AUTOSAR XML (schema 00044)
package /ComponentTypes
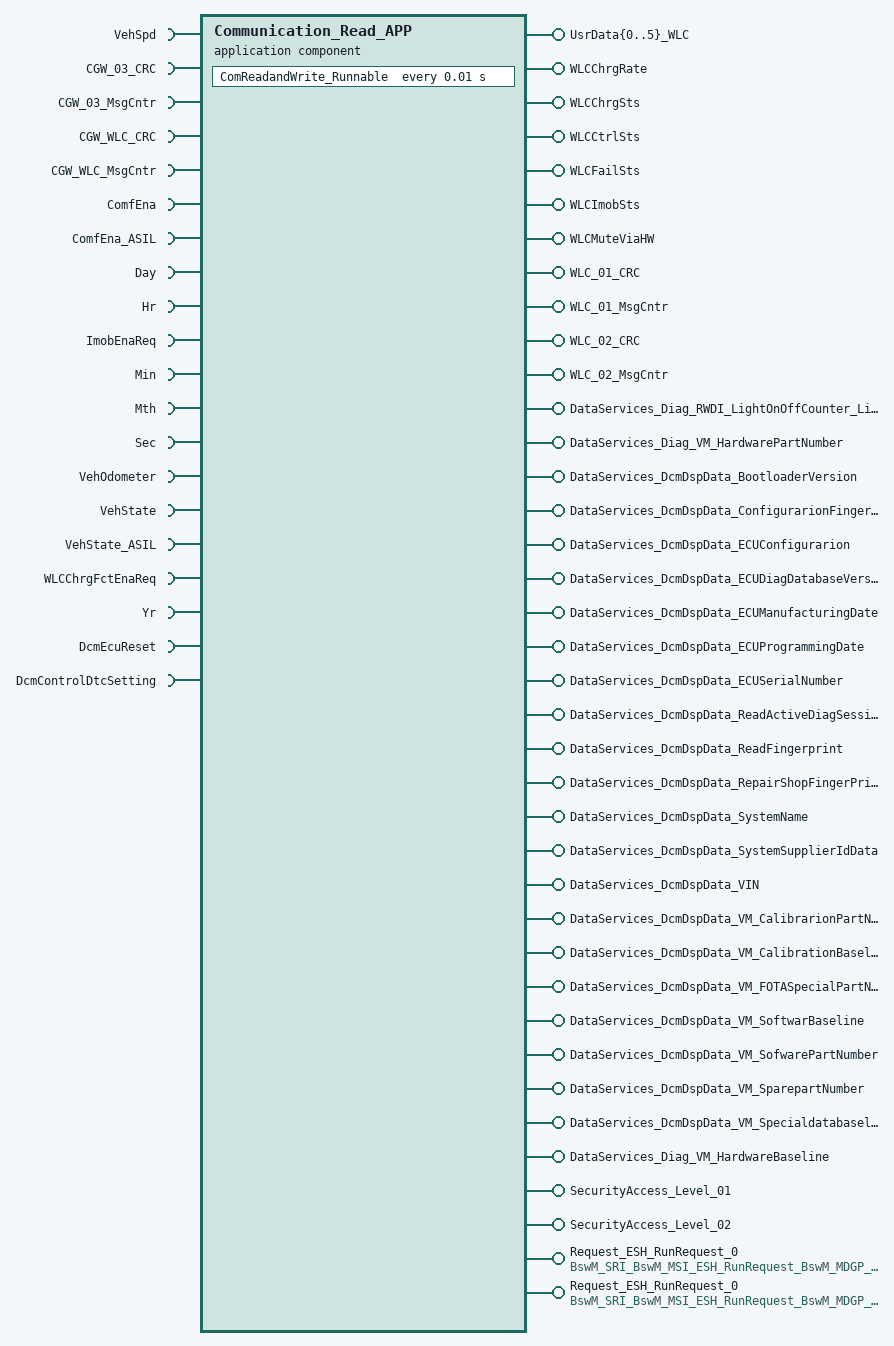
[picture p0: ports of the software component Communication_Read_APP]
  application sw component type Communication_Read_APP
    18 x require port:
      VehSpd: nonqueued-receiver-com-spec{data-element=VehSpd, filter=data-filter-type=ALWAYS, init-value=0}, required-interface=VehSpd
      CGW_03_CRC: nonqueued-receiver-com-spec{data-element=CGW_03_CRC, filter=data-filter-type=ALWAYS, init-value=0}, required-interface=CGW_03_CRC
      CGW_03_MsgCntr: nonqueued-receiver-com-spec{data-element=CGW_03_MsgCntr, filter=data-filter-type=ALWAYS, init-value=0}, required-interface=CGW_03_MsgCntr
      CGW_WLC_CRC: nonqueued-receiver-com-spec{data-element=CGW_WLC_CRC, filter=data-filter-type=ALWAYS, init-value=0}, required-interface=CGW_WLC_CRC
      CGW_WLC_MsgCntr: nonqueued-receiver-com-spec{data-element=CGW_WLC_MsgCntr, filter=data-filter-type=ALWAYS, init-value=0}, required-interface=CGW_WLC_MsgCntr
      ComfEna: nonqueued-receiver-com-spec{data-element=ComfEna, filter=data-filter-type=ALWAYS, init-value=0}, required-interface=ComfEna
      ComfEna_ASIL: nonqueued-receiver-com-spec{data-element=ComfEna_ASIL, filter=data-filter-type=ALWAYS, init-value=0}, required-interface=ComfEna_ASIL
      Day: nonqueued-receiver-com-spec{data-element=Day, filter=data-filter-type=ALWAYS, init-value=0}, required-interface=Day
      Hr: nonqueued-receiver-com-spec{data-element=Hr, filter=data-filter-type=ALWAYS, init-value=0}, required-interface=Hr
      ImobEnaReq: nonqueued-receiver-com-spec{data-element=ImobEnaReq, filter=data-filter-type=ALWAYS, init-value=0}, required-interface=ImobEnaReq
      Min: nonqueued-receiver-com-spec{data-element=Min, filter=data-filter-type=ALWAYS, init-value=0}, required-interface=Min
      Mth: nonqueued-receiver-com-spec{data-element=Mth, filter=data-filter-type=ALWAYS, init-value=0}, required-interface=Mth
      Sec: nonqueued-receiver-com-spec{data-element=Sec, filter=data-filter-type=ALWAYS, init-value=0}, required-interface=Sec
      VehOdometer: nonqueued-receiver-com-spec{data-element=VehOdometer, filter=data-filter-type=ALWAYS, init-value=0}, required-interface=VehOdometer
      VehState: nonqueued-receiver-com-spec{data-element=VehState, filter=data-filter-type=ALWAYS, init-value=0}, required-interface=VehState
      VehState_ASIL: nonqueued-receiver-com-spec{data-element=VehState_ASIL, filter=data-filter-type=ALWAYS, init-value=0}, required-interface=VehState_ASIL
      WLCChrgFctEnaReq: nonqueued-receiver-com-spec{data-element=WLCChrgFctEnaReq, filter=data-filter-type=ALWAYS, init-value=0}, required-interface=WLCChrgFctEnaReq
      Yr: nonqueued-receiver-com-spec{data-element=Yr, filter=data-filter-type=ALWAYS, init-value=0}, required-interface=Yr
    16 x provide port:
      UsrData{0..5}_WLC: nonqueued-sender-com-spec{data-element=UsrData{0..5}_WLC, init-value=0}, provided-interface=UsrData{0..5}_WLC
      WLCChrgRate: nonqueued-sender-com-spec{data-element=WLCChrgRate, init-value=0}, provided-interface=WLCChrgRate
      WLCChrgSts: nonqueued-sender-com-spec{data-element=WLCChrgSts, init-value=0}, provided-interface=WLCChrgSts
      WLCCtrlSts: nonqueued-sender-com-spec{data-element=WLCCtrlSts, init-value=0}, provided-interface=WLCCtrlSts
      WLCFailSts: nonqueued-sender-com-spec{data-element=WLCFailSts, init-value=0}, provided-interface=WLCFailSts
      WLCImobSts: nonqueued-sender-com-spec{data-element=WLCImobSts, init-value=0}, provided-interface=WLCImobSts
      WLCMuteViaHW: nonqueued-sender-com-spec{data-element=WLCMuteViaHW, init-value=0}, provided-interface=WLCMuteViaHW
      WLC_01_CRC: nonqueued-sender-com-spec{data-element=WLC_01_CRC, init-value=0}, provided-interface=WLC_01_CRC
      WLC_01_MsgCntr: nonqueued-sender-com-spec{data-element=WLC_01_MsgCntr, init-value=0}, provided-interface=WLC_01_MsgCntr
      WLC_02_CRC: nonqueued-sender-com-spec{data-element=WLC_02_CRC, init-value=0}, provided-interface=WLC_02_CRC
      WLC_02_MsgCntr: nonqueued-sender-com-spec{data-element=WLC_02_MsgCntr, init-value=0}, provided-interface=WLC_02_MsgCntr
    require port DcmEcuReset: mode-switch-receiver-com-spec=DcmEcuReset, required-interface=DcmEcuReset
    23 x provide port:
      DataServices_Diag_RWDI_LightOnOffCounter_LightOnOffCounter_Value: provided-interface=DataServices_Diag_RWDI_LightOnOffCounter_LightOnOffCounter_Value
        provided-com-specs:
          operation=ReadData, queue-length=1
          operation=ConditionCheckRead, queue-length=1
          operation=WriteData, queue-length=1
      DataServices_Diag_VM_HardwarePartNumber: provided-interface=DataServices_Diag_VM_HardwarePartNumber
        provided-com-specs:
          operation=ReadData, queue-length=1
          operation=ConditionCheckRead, queue-length=1
          operation=WriteData, queue-length=1
      DataServices_DcmDspData_BootloaderVersion: provided-interface=DataServices_DcmDspData_BootloaderVersion
        provided-com-specs:
          operation=ReadData, queue-length=1
          operation=ReadDataLength, queue-length=1
          operation=ConditionCheckRead, queue-length=1
      DataServices_DcmDspData_ConfigurarionFingerprint: provided-interface=DataServices_DcmDspData_ConfigurarionFingerprint
        provided-com-specs:
          operation=ReadData, queue-length=1
          operation=ConditionCheckRead, queue-length=1
          operation=WriteData, queue-length=1
      DataServices_DcmDspData_ECUConfigurarion: provided-interface=DataServices_DcmDspData_ECUConfigurarion
        provided-com-specs:
          operation=ReadData, queue-length=1
          operation=ConditionCheckRead, queue-length=1
          operation=WriteData, queue-length=1
      DataServices_DcmDspData_ECUDiagDatabaseVersion: provided-com-specs=[{operation=ReadData, queue-length=1}, {operation=ConditionCheckRead, queue-length=1}], provided-interface=DataServices_DcmDspData_ECUDiagDatabaseVersion
      DataServices_DcmDspData_ECUManufacturingDate: provided-com-specs=[{operation=ReadData, queue-length=1}, {operation=ConditionCheckRead, queue-length=1}], provided-interface=DataServices_DcmDspData_ECUManufacturingDate
      DataServices_DcmDspData_ECUProgrammingDate: provided-com-specs=[{operation=ReadData, queue-length=1}, {operation=ConditionCheckRead, queue-length=1}], provided-interface=DataServices_DcmDspData_ECUProgrammingDate
      DataServices_DcmDspData_ECUSerialNumber: provided-com-specs=[{operation=ReadData, queue-length=1}, {operation=ConditionCheckRead, queue-length=1}], provided-interface=DataServices_DcmDspData_ECUSerialNumber
      DataServices_DcmDspData_ReadActiveDiagSession: provided-com-specs=[{operation=ReadData, queue-length=1}, {operation=ConditionCheckRead, queue-length=1}], provided-interface=DataServices_DcmDspData_ReadActiveDiagSession
      DataServices_DcmDspData_ReadFingerprint: provided-com-specs=[{operation=ReadData, queue-length=1}, {operation=ConditionCheckRead, queue-length=1}], provided-interface=DataServices_DcmDspData_ReadFingerprint
      DataServices_DcmDspData_RepairShopFingerPrint: provided-interface=DataServices_DcmDspData_RepairShopFingerPrint
        provided-com-specs:
          operation=ReadData, queue-length=1
          operation=ConditionCheckRead, queue-length=1
          operation=WriteData, queue-length=1
      DataServices_DcmDspData_SystemName: provided-interface=DataServices_DcmDspData_SystemName
        provided-com-specs:
          operation=ReadData, queue-length=1
          operation=ReadDataLength, queue-length=1
          operation=ConditionCheckRead, queue-length=1
      DataServices_DcmDspData_SystemSupplierIdData: provided-com-specs=[{operation=ReadData, queue-length=1}, {operation=ConditionCheckRead, queue-length=1}], provided-interface=DataServices_DcmDspData_SystemSupplierIdData
      DataServices_DcmDspData_VIN: provided-interface=DataServices_DcmDspData_VIN
        provided-com-specs:
          operation=ReadData, queue-length=1
          operation=ConditionCheckRead, queue-length=1
          operation=WriteData, queue-length=1
      DataServices_DcmDspData_VM_CalibrarionPartNumber: provided-interface=DataServices_DcmDspData_VM_CalibrarionPartNumber
        provided-com-specs:
          operation=ReadData, queue-length=1
          operation=ConditionCheckRead, queue-length=1
          operation=WriteData, queue-length=1
      DataServices_DcmDspData_VM_CalibrationBaseline: provided-interface=DataServices_DcmDspData_VM_CalibrationBaseline
        provided-com-specs:
          operation=ReadData, queue-length=1
          operation=ConditionCheckRead, queue-length=1
          operation=WriteData, queue-length=1
      DataServices_DcmDspData_VM_FOTASpecialPartNumber: provided-interface=DataServices_DcmDspData_VM_FOTASpecialPartNumber
        provided-com-specs:
          operation=ReadData, queue-length=1
          operation=ConditionCheckRead, queue-length=1
          operation=WriteData, queue-length=1
      DataServices_DcmDspData_VM_SoftwarBaseline: provided-interface=DataServices_DcmDspData_VM_SoftwarBaseline
        provided-com-specs:
          operation=ReadData, queue-length=1
          operation=ConditionCheckRead, queue-length=1
          operation=WriteData, queue-length=1
      DataServices_DcmDspData_VM_SofwarePartNumber: provided-interface=DataServices_DcmDspData_VM_SofwarePartNumber
        provided-com-specs:
          operation=ReadData, queue-length=1
          operation=ConditionCheckRead, queue-length=1
          operation=WriteData, queue-length=1
      DataServices_DcmDspData_VM_SparepartNumber: provided-interface=DataServices_DcmDspData_VM_SparepartNumber
        provided-com-specs:
          operation=ReadData, queue-length=1
          operation=ConditionCheckRead, queue-length=1
          operation=WriteData, queue-length=1
      DataServices_DcmDspData_VM_Specialdatabaseline: provided-interface=DataServices_DcmDspData_VM_Specialdatabaseline
        provided-com-specs:
          operation=ReadData, queue-length=1
          operation=ReadDataLength, queue-length=1
          operation=ConditionCheckRead, queue-length=1
          operation=WriteData, queue-length=1
      DataServices_Diag_VM_HardwareBaseline: provided-interface=DataServices_Diag_VM_HardwareBaseline
        provided-com-specs:
          operation=ReadData, queue-length=1
          operation=ConditionCheckRead, queue-length=1
          operation=WriteData, queue-length=1
    require port DcmControlDtcSetting: mode-switch-receiver-com-spec=DcmControlDtcSetting, required-interface=DcmControlDtcSetting
    4 x provide port:
      SecurityAccess_Level_01: provided-com-specs=[{operation=GetSeed, queue-length=1}, {operation=CompareKey, queue-length=1}], provided-interface=SecurityAccess_Level_01
      SecurityAccess_Level_02: provided-com-specs=[{operation=GetSeed, queue-length=1}, {operation=CompareKey, queue-length=1}], provided-interface=SecurityAccess_Level_02
      Request_ESH_RunRequest_0: nonqueued-sender-com-spec=requestedMode, provided-interface=BswM_SRI_BswM_MSI_ESH_RunRequest_BswM_MDGP_ESH_RunRequest
      Request_ESH_RunRequest_0: nonqueued-sender-com-spec=requestedMode, provided-interface=BswM_SRI_BswM_MSI_ESH_RunRequest_BswM_MDGP_ESH_RunRequest
    behavior Communication_Read_APP_InternalBehavior
      timing event TMT_WLCAPP_Runnable: start-on-event=ComReadandWrite_Runnable, period=0.01
      67 x operation invoked event:
        OIT_DataServices_Diag_RWDI_LightOnOffCounter_LightOnOffCounter_Value_WriteData_DataServices_Diag_RWDI_LightOnOffCounter_9798F8A6: start-on-event=DataServices_Diag_RWDI_LightOnOffCounter_LightOnOffCounter_Value_WriteData, operation=DataServices_Diag_RWDI_LightOnOffCounter_LightOnOffCounter_Value.WriteData
        OIT_DataServices_Diag_RWDI_LightOnOffCounter_LightOnOffCounter_Value_ConditionCheckRead_DataServices_Diag_RWDI_LightOnOf2065F94A: start-on-event=DataServices_Diag_RWDI_LightOnOffCounter_LightOnOffCounter_Value_ConditionCheckRead, operation=DataServices_Diag_RWDI_LightOnOffCounter_LightOnOffCounter_Value.ConditionCheckRead
        OIT_DataServices_Diag_RWDI_LightOnOffCounter_LightOnOffCounter_Value_ReadData_DataServices_Diag_RWDI_LightOnOffCounter_LBCB6C10A: start-on-event=DataServices_Diag_RWDI_LightOnOffCounter_LightOnOffCounter_Value_ReadData, operation=DataServices_Diag_RWDI_LightOnOffCounter_LightOnOffCounter_Value.ReadData
        OIT_DataServices_Diag_VM_HardwarePartNumber_WriteData_DataServices_Diag_VM_HardwarePartNumber_WriteData: start-on-event=DataServices_Diag_VM_HardwarePartNumber_WriteData, operation=DataServices_Diag_VM_HardwarePartNumber.WriteData
        OIT_DataServices_Diag_VM_HardwarePartNumber_ConditionCheckRead_DataServices_Diag_VM_HardwarePartNumber_ConditionCheckRead: start-on-event=DataServices_Diag_VM_HardwarePartNumber_ConditionCheckRead, operation=DataServices_Diag_VM_HardwarePartNumber.ConditionCheckRead
        OIT_DataServices_Diag_VM_HardwarePartNumber_ReadData_DataServices_Diag_VM_HardwarePartNumber_ReadData: start-on-event=DataServices_Diag_VM_HardwarePartNumber_ReadData, operation=DataServices_Diag_VM_HardwarePartNumber.ReadData
        OIT_DataServices_DcmDspData_BootloaderVersion_ConditionCheckRead_DataServices_DcmDspData_BootloaderVersion_ConditionCheckRead: start-on-event=DataServices_DcmDspData_BootloaderVersion_ConditionCheckRead, operation=DataServices_DcmDspData_BootloaderVersion.ConditionCheckRead
        OIT_DataServices_DcmDspData_BootloaderVersion_ReadDataLength_DataServices_DcmDspData_BootloaderVersion_ReadDataLength: start-on-event=DataServices_DcmDspData_BootloaderVersion_ReadDataLength, operation=DataServices_DcmDspData_BootloaderVersion.ReadDataLength
        OIT_DataServices_DcmDspData_BootloaderVersion_ReadData_DataServices_DcmDspData_BootloaderVersion_ReadData: start-on-event=DataServices_DcmDspData_BootloaderVersion_ReadData, operation=DataServices_DcmDspData_BootloaderVersion.ReadData
        OIT_DataServices_DcmDspData_ConfigurarionFingerprint_WriteData_DataServices_DcmDspData_ConfigurarionFingerprint_WriteData: start-on-event=DataServices_DcmDspData_ConfigurarionFingerprint_WriteData, operation=DataServices_DcmDspData_ConfigurarionFingerprint.WriteData
        OIT_DataServices_DcmDspData_ConfigurarionFingerprint_ConditionCheckRead_DataServices_DcmDspData_ConfigurarionFingerprint8B465459: start-on-event=DataServices_DcmDspData_ConfigurarionFingerprint_ConditionCheckRead, operation=DataServices_DcmDspData_ConfigurarionFingerprint.ConditionCheckRead
        OIT_DataServices_DcmDspData_ConfigurarionFingerprint_ReadData_DataServices_DcmDspData_ConfigurarionFingerprint_ReadData: start-on-event=DataServices_DcmDspData_ConfigurarionFingerprint_ReadData, operation=DataServices_DcmDspData_ConfigurarionFingerprint.ReadData
        OIT_DataServices_DcmDspData_ECUConfigurarion_WriteData_DataServices_DcmDspData_ECUConfigurarion_WriteData: start-on-event=DataServices_DcmDspData_ECUConfigurarion_WriteData, operation=DataServices_DcmDspData_ECUConfigurarion.WriteData
        OIT_DataServices_DcmDspData_ECUConfigurarion_ConditionCheckRead_DataServices_DcmDspData_ECUConfigurarion_ConditionCheckRead: start-on-event=DataServices_DcmDspData_ECUConfigurarion_ConditionCheckRead, operation=DataServices_DcmDspData_ECUConfigurarion.ConditionCheckRead
        OIT_DataServices_DcmDspData_ECUConfigurarion_ReadData_DataServices_DcmDspData_ECUConfigurarion_ReadData: start-on-event=DataServices_DcmDspData_ECUConfigurarion_ReadData, operation=DataServices_DcmDspData_ECUConfigurarion.ReadData
        OIT_DataServices_DcmDspData_ECUDiagDatabaseVersion_ConditionCheckRead_DataServices_DcmDspData_ECUDiagDatabaseVersion_Con898CC0D4: start-on-event=DataServices_DcmDspData_ECUDiagDatabaseVersion_ConditionCheckRead, operation=DataServices_DcmDspData_ECUDiagDatabaseVersion.ConditionCheckRead
        OIT_DataServices_DcmDspData_ECUDiagDatabaseVersion_ReadData_DataServices_DcmDspData_ECUDiagDatabaseVersion_ReadData: start-on-event=DataServices_DcmDspData_ECUDiagDatabaseVersion_ReadData, operation=DataServices_DcmDspData_ECUDiagDatabaseVersion.ReadData
        OIT_DataServices_DcmDspData_ECUManufacturingDate_ConditionCheckRead_DataServices_DcmDspData_ECUManufacturingDate_Conditi36A93663: start-on-event=DataServices_DcmDspData_ECUManufacturingDate_ConditionCheckRead, operation=DataServices_DcmDspData_ECUManufacturingDate.ConditionCheckRead
        OIT_DataServices_DcmDspData_ECUManufacturingDate_ReadData_DataServices_DcmDspData_ECUManufacturingDate_ReadData: start-on-event=DataServices_DcmDspData_ECUManufacturingDate_ReadData, operation=DataServices_DcmDspData_ECUManufacturingDate.ReadData
        OIT_DataServices_DcmDspData_ECUProgrammingDate_ConditionCheckRead_DataServices_DcmDspData_ECUProgrammingDate_ConditionCheckRead: start-on-event=DataServices_DcmDspData_ECUProgrammingDate_ConditionCheckRead, operation=DataServices_DcmDspData_ECUProgrammingDate.ConditionCheckRead
        OIT_DataServices_DcmDspData_ECUProgrammingDate_ReadData_DataServices_DcmDspData_ECUProgrammingDate_ReadData: start-on-event=DataServices_DcmDspData_ECUProgrammingDate_ReadData, operation=DataServices_DcmDspData_ECUProgrammingDate.ReadData
        OIT_DataServices_DcmDspData_ECUSerialNumber_ConditionCheckRead_DataServices_DcmDspData_ECUSerialNumber_ConditionCheckRead: start-on-event=DataServices_DcmDspData_ECUSerialNumber_ConditionCheckRead, operation=DataServices_DcmDspData_ECUSerialNumber.ConditionCheckRead
        OIT_DataServices_DcmDspData_ECUSerialNumber_ReadData_DataServices_DcmDspData_ECUSerialNumber_ReadData: start-on-event=DataServices_DcmDspData_ECUSerialNumber_ReadData, operation=DataServices_DcmDspData_ECUSerialNumber.ReadData
        OIT_DataServices_DcmDspData_ReadActiveDiagSession_ConditionCheckRead_DataServices_DcmDspData_ReadActiveDiagSession_Condi595C28B7: start-on-event=DataServices_DcmDspData_ReadActiveDiagSession_ConditionCheckRead, operation=DataServices_DcmDspData_ReadActiveDiagSession.ConditionCheckRead
        OIT_DataServices_DcmDspData_ReadActiveDiagSession_ReadData_DataServices_DcmDspData_ReadActiveDiagSession_ReadData: start-on-event=DataServices_DcmDspData_ReadActiveDiagSession_ReadData, operation=DataServices_DcmDspData_ReadActiveDiagSession.ReadData
        OIT_DataServices_DcmDspData_ReadFingerprint_ConditionCheckRead_DataServices_DcmDspData_ReadFingerprint_ConditionCheckRead: start-on-event=DataServices_DcmDspData_ReadFingerprint_ConditionCheckRead, operation=DataServices_DcmDspData_ReadFingerprint.ConditionCheckRead
        OIT_DataServices_DcmDspData_ReadFingerprint_ReadData_DataServices_DcmDspData_ReadFingerprint_ReadData: start-on-event=DataServices_DcmDspData_ReadFingerprint_ReadData, operation=DataServices_DcmDspData_ReadFingerprint.ReadData
        OIT_DataServices_DcmDspData_RepairShopFingerPrint_WriteData_DataServices_DcmDspData_RepairShopFingerPrint_WriteData: start-on-event=DataServices_DcmDspData_RepairShopFingerPrint_WriteData, operation=DataServices_DcmDspData_RepairShopFingerPrint.WriteData
        OIT_DataServices_DcmDspData_RepairShopFingerPrint_ConditionCheckRead_DataServices_DcmDspData_RepairShopFingerPrint_CondiF74E6915: start-on-event=DataServices_DcmDspData_RepairShopFingerPrint_ConditionCheckRead, operation=DataServices_DcmDspData_RepairShopFingerPrint.ConditionCheckRead
        OIT_DataServices_DcmDspData_RepairShopFingerPrint_ReadData_DataServices_DcmDspData_RepairShopFingerPrint_ReadData: start-on-event=DataServices_DcmDspData_RepairShopFingerPrint_ReadData, operation=DataServices_DcmDspData_RepairShopFingerPrint.ReadData
        OIT_DataServices_DcmDspData_SystemName_ConditionCheckRead_DataServices_DcmDspData_SystemName_ConditionCheckRead: start-on-event=DataServices_DcmDspData_SystemName_ConditionCheckRead, operation=DataServices_DcmDspData_SystemName.ConditionCheckRead
        OIT_DataServices_DcmDspData_SystemName_ReadDataLength_DataServices_DcmDspData_SystemName_ReadDataLength: start-on-event=DataServices_DcmDspData_SystemName_ReadDataLength, operation=DataServices_DcmDspData_SystemName.ReadDataLength
        OIT_DataServices_DcmDspData_SystemName_ReadData_DataServices_DcmDspData_SystemName_ReadData: start-on-event=DataServices_DcmDspData_SystemName_ReadData, operation=DataServices_DcmDspData_SystemName.ReadData
        OIT_DataServices_DcmDspData_SystemSupplierIdData_ConditionCheckRead_DataServices_DcmDspData_SystemSupplierIdData_Conditi555B98AA: start-on-event=DataServices_DcmDspData_SystemSupplierIdData_ConditionCheckRead, operation=DataServices_DcmDspData_SystemSupplierIdData.ConditionCheckRead
        OIT_DataServices_DcmDspData_SystemSupplierIdData_ReadData_DataServices_DcmDspData_SystemSupplierIdData_ReadData: start-on-event=DataServices_DcmDspData_SystemSupplierIdData_ReadData, operation=DataServices_DcmDspData_SystemSupplierIdData.ReadData
        OIT_DataServices_DcmDspData_VIN_WriteData_DataServices_DcmDspData_VIN_WriteData: start-on-event=DataServices_DcmDspData_VIN_WriteData, operation=DataServices_DcmDspData_VIN.WriteData
        OIT_DataServices_DcmDspData_VIN_ConditionCheckRead_DataServices_DcmDspData_VIN_ConditionCheckRead: start-on-event=DataServices_DcmDspData_VIN_ConditionCheckRead, operation=DataServices_DcmDspData_VIN.ConditionCheckRead
        OIT_DataServices_DcmDspData_VIN_ReadData_DataServices_DcmDspData_VIN_ReadData: start-on-event=DataServices_DcmDspData_VIN_ReadData, operation=DataServices_DcmDspData_VIN.ReadData
        OIT_DataServices_DcmDspData_VM_CalibrarionPartNumber_WriteData_DataServices_DcmDspData_VM_CalibrarionPartNumber_WriteData: start-on-event=DataServices_DcmDspData_VM_CalibrarionPartNumber_WriteData, operation=DataServices_DcmDspData_VM_CalibrarionPartNumber.WriteData
        OIT_DataServices_DcmDspData_VM_CalibrarionPartNumber_ConditionCheckRead_DataServices_DcmDspData_VM_CalibrarionPartNumber03305360: start-on-event=DataServices_DcmDspData_VM_CalibrarionPartNumber_ConditionCheckRead, operation=DataServices_DcmDspData_VM_CalibrarionPartNumber.ConditionCheckRead
        OIT_DataServices_DcmDspData_VM_CalibrarionPartNumber_ReadData_DataServices_DcmDspData_VM_CalibrarionPartNumber_ReadData: start-on-event=DataServices_DcmDspData_VM_CalibrarionPartNumber_ReadData, operation=DataServices_DcmDspData_VM_CalibrarionPartNumber.ReadData
        OIT_DataServices_DcmDspData_VM_CalibrationBaseline_WriteData_DataServices_DcmDspData_VM_CalibrationBaseline_WriteData: start-on-event=DataServices_DcmDspData_VM_CalibrationBaseline_WriteData, operation=DataServices_DcmDspData_VM_CalibrationBaseline.WriteData
        OIT_DataServices_DcmDspData_VM_CalibrationBaseline_ConditionCheckRead_DataServices_DcmDspData_VM_CalibrationBaseline_Con9CE12721: start-on-event=DataServices_DcmDspData_VM_CalibrationBaseline_ConditionCheckRead, operation=DataServices_DcmDspData_VM_CalibrationBaseline.ConditionCheckRead
        OIT_DataServices_DcmDspData_VM_CalibrationBaseline_ReadData_DataServices_DcmDspData_VM_CalibrationBaseline_ReadData: start-on-event=DataServices_DcmDspData_VM_CalibrationBaseline_ReadData, operation=DataServices_DcmDspData_VM_CalibrationBaseline.ReadData
        OIT_DataServices_DcmDspData_VM_FOTASpecialPartNumber_WriteData_DataServices_DcmDspData_VM_FOTASpecialPartNumber_WriteData: start-on-event=DataServices_DcmDspData_VM_FOTASpecialPartNumber_WriteData, operation=DataServices_DcmDspData_VM_FOTASpecialPartNumber.WriteData
        OIT_DataServices_DcmDspData_VM_FOTASpecialPartNumber_ConditionCheckRead_DataServices_DcmDspData_VM_FOTASpecialPartNumber12F56527: start-on-event=DataServices_DcmDspData_VM_FOTASpecialPartNumber_ConditionCheckRead, operation=DataServices_DcmDspData_VM_FOTASpecialPartNumber.ConditionCheckRead
        OIT_DataServices_DcmDspData_VM_FOTASpecialPartNumber_ReadData_DataServices_DcmDspData_VM_FOTASpecialPartNumber_ReadData: start-on-event=DataServices_DcmDspData_VM_FOTASpecialPartNumber_ReadData, operation=DataServices_DcmDspData_VM_FOTASpecialPartNumber.ReadData
        OIT_DataServices_DcmDspData_VM_SoftwarBaseline_WriteData_DataServices_DcmDspData_VM_SoftwarBaseline_WriteData: start-on-event=DataServices_DcmDspData_VM_SoftwarBaseline_WriteData, operation=DataServices_DcmDspData_VM_SoftwarBaseline.WriteData
        OIT_DataServices_DcmDspData_VM_SoftwarBaseline_ConditionCheckRead_DataServices_DcmDspData_VM_SoftwarBaseline_ConditionCheckRead: start-on-event=DataServices_DcmDspData_VM_SoftwarBaseline_ConditionCheckRead, operation=DataServices_DcmDspData_VM_SoftwarBaseline.ConditionCheckRead
        OIT_DataServices_DcmDspData_VM_SoftwarBaseline_ReadData_DataServices_DcmDspData_VM_SoftwarBaseline_ReadData: start-on-event=DataServices_DcmDspData_VM_SoftwarBaseline_ReadData, operation=DataServices_DcmDspData_VM_SoftwarBaseline.ReadData
        OIT_DataServices_DcmDspData_VM_SofwarePartNumber_WriteData_DataServices_DcmDspData_VM_SofwarePartNumber_WriteData: start-on-event=DataServices_DcmDspData_VM_SofwarePartNumber_WriteData, operation=DataServices_DcmDspData_VM_SofwarePartNumber.WriteData
        OIT_DataServices_DcmDspData_VM_SofwarePartNumber_ConditionCheckRead_DataServices_DcmDspData_VM_SofwarePartNumber_ConditiA041C6FF: start-on-event=DataServices_DcmDspData_VM_SofwarePartNumber_ConditionCheckRead, operation=DataServices_DcmDspData_VM_SofwarePartNumber.ConditionCheckRead
        OIT_DataServices_DcmDspData_VM_SofwarePartNumber_ReadData_DataServices_DcmDspData_VM_SofwarePartNumber_ReadData: start-on-event=DataServices_DcmDspData_VM_SofwarePartNumber_ReadData, operation=DataServices_DcmDspData_VM_SofwarePartNumber.ReadData
        OIT_DataServices_DcmDspData_VM_SparepartNumber_WriteData_DataServices_DcmDspData_VM_SparepartNumber_WriteData: start-on-event=DataServices_DcmDspData_VM_SparepartNumber_WriteData, operation=DataServices_DcmDspData_VM_SparepartNumber.WriteData
        OIT_DataServices_DcmDspData_VM_SparepartNumber_ConditionCheckRead_DataServices_DcmDspData_VM_SparepartNumber_ConditionCheckRead: start-on-event=DataServices_DcmDspData_VM_SparepartNumber_ConditionCheckRead, operation=DataServices_DcmDspData_VM_SparepartNumber.ConditionCheckRead
        OIT_DataServices_DcmDspData_VM_SparepartNumber_ReadData_DataServices_DcmDspData_VM_SparepartNumber_ReadData: start-on-event=DataServices_DcmDspData_VM_SparepartNumber_ReadData, operation=DataServices_DcmDspData_VM_SparepartNumber.ReadData
        OIT_DataServices_DcmDspData_VM_Specialdatabaseline_WriteData_DataServices_DcmDspData_VM_Specialdatabaseline_WriteData: start-on-event=DataServices_DcmDspData_VM_Specialdatabaseline_WriteData, operation=DataServices_DcmDspData_VM_Specialdatabaseline.WriteData
        OIT_DataServices_DcmDspData_VM_Specialdatabaseline_ConditionCheckRead_DataServices_DcmDspData_VM_Specialdatabaseline_Con3B7A3020: start-on-event=DataServices_DcmDspData_VM_Specialdatabaseline_ConditionCheckRead, operation=DataServices_DcmDspData_VM_Specialdatabaseline.ConditionCheckRead
        OIT_DataServices_DcmDspData_VM_Specialdatabaseline_ReadDataLength_DataServices_DcmDspData_VM_Specialdatabaseline_ReadDataLength: start-on-event=DataServices_DcmDspData_VM_Specialdatabaseline_ReadDataLength, operation=DataServices_DcmDspData_VM_Specialdatabaseline.ReadDataLength
        OIT_DataServices_DcmDspData_VM_Specialdatabaseline_ReadData_DataServices_DcmDspData_VM_Specialdatabaseline_ReadData: start-on-event=DataServices_DcmDspData_VM_Specialdatabaseline_ReadData, operation=DataServices_DcmDspData_VM_Specialdatabaseline.ReadData
        OIT_DataServices_Diag_VM_HardwareBaseline_WriteData_DataServices_Diag_VM_HardwareBaseline_WriteData: start-on-event=DataServices_Diag_VM_HardwareBaseline_WriteData, operation=DataServices_Diag_VM_HardwareBaseline.WriteData
        OIT_DataServices_Diag_VM_HardwareBaseline_ConditionCheckRead_DataServices_Diag_VM_HardwareBaseline_ConditionCheckRead: start-on-event=DataServices_Diag_VM_HardwareBaseline_ConditionCheckRead, operation=DataServices_Diag_VM_HardwareBaseline.ConditionCheckRead
        OIT_DataServices_Diag_VM_HardwareBaseline_ReadData_DataServices_Diag_VM_HardwareBaseline_ReadData: start-on-event=DataServices_Diag_VM_HardwareBaseline_ReadData, operation=DataServices_Diag_VM_HardwareBaseline.ReadData
        OIT_SecurityAccess_Level_01_CompareKey_SecurityAccess_Level_01_CompareKey: start-on-event=SecurityAccess_Level_01_CompareKey, operation=SecurityAccess_Level_01.CompareKey
        OIT_SecurityAccess_Level_01_GetSeed_SecurityAccess_Level_01_GetSeed: start-on-event=SecurityAccess_Level_01_GetSeed, operation=SecurityAccess_Level_01.GetSeed
        OIT_SecurityAccess_Level_02_CompareKey_SecurityAccess_Level_02_CompareKey: start-on-event=SecurityAccess_Level_02_CompareKey, operation=SecurityAccess_Level_02.CompareKey
        OIT_SecurityAccess_Level_02_GetSeed_SecurityAccess_Level_02_GetSeed: start-on-event=SecurityAccess_Level_02_GetSeed, operation=SecurityAccess_Level_02.GetSeed
      68 x runnable:
        ComReadandWrite_Runnable: mode-access-point=DcmEcuReset.DcmEcuReset
          data-receive-point-by-arguments:
            18 x access:
              REC_VehSpd_VehSpd: accessed-variable=VehSpd.VehSpd
              REC_CGW_03_CRC_CGW_03_CRC: accessed-variable=CGW_03_CRC.CGW_03_CRC
              REC_CGW_03_MsgCntr_CGW_03_MsgCntr: accessed-variable=CGW_03_MsgCntr.CGW_03_MsgCntr
              REC_CGW_WLC_CRC_CGW_WLC_CRC: accessed-variable=CGW_WLC_CRC.CGW_WLC_CRC
              REC_CGW_WLC_MsgCntr_CGW_WLC_MsgCntr: accessed-variable=CGW_WLC_MsgCntr.CGW_WLC_MsgCntr
              REC_ComfEna_ComfEna: accessed-variable=ComfEna.ComfEna
              REC_ComfEna_ASIL_ComfEna_ASIL: accessed-variable=ComfEna_ASIL.ComfEna_ASIL
              REC_Day_Day: accessed-variable=Day.Day
              REC_Hr_Hr: accessed-variable=Hr.Hr
              REC_ImobEnaReq_ImobEnaReq: accessed-variable=ImobEnaReq.ImobEnaReq
              REC_Min_Min: accessed-variable=Min.Min
              REC_Mth_Mth: accessed-variable=Mth.Mth
              REC_Sec_Sec: accessed-variable=Sec.Sec
              REC_VehOdometer_VehOdometer: accessed-variable=VehOdometer.VehOdometer
              REC_VehState_VehState: accessed-variable=VehState.VehState
              REC_VehState_ASIL_VehState_ASIL: accessed-variable=VehState_ASIL.VehState_ASIL
              REC_WLCChrgFctEnaReq_WLCChrgFctEnaReq: accessed-variable=WLCChrgFctEnaReq.WLCChrgFctEnaReq
              REC_Yr_Yr: accessed-variable=Yr.Yr
          data-send-points:
            16 x access:
              SEND_UsrData{0..5}_WLC_UsrData{0..5}_WLC: accessed-variable=UsrData{0..5}_WLC.UsrData{0..5}_WLC
              SEND_WLCChrgRate_WLCChrgRate: accessed-variable=WLCChrgRate.WLCChrgRate
              SEND_WLCChrgSts_WLCChrgSts: accessed-variable=WLCChrgSts.WLCChrgSts
              SEND_WLCCtrlSts_WLCCtrlSts: accessed-variable=WLCCtrlSts.WLCCtrlSts
              SEND_WLCFailSts_WLCFailSts: accessed-variable=WLCFailSts.WLCFailSts
              SEND_WLCImobSts_WLCImobSts: accessed-variable=WLCImobSts.WLCImobSts
              SEND_WLCMuteViaHW_WLCMuteViaHW: accessed-variable=WLCMuteViaHW.WLCMuteViaHW
              SEND_WLC_01_CRC_WLC_01_CRC: accessed-variable=WLC_01_CRC.WLC_01_CRC
              SEND_WLC_01_MsgCntr_WLC_01_MsgCntr: accessed-variable=WLC_01_MsgCntr.WLC_01_MsgCntr
              SEND_WLC_02_CRC_WLC_02_CRC: accessed-variable=WLC_02_CRC.WLC_02_CRC
              SEND_WLC_02_MsgCntr_WLC_02_MsgCntr: accessed-variable=WLC_02_MsgCntr.WLC_02_MsgCntr
        DataServices_Diag_RWDI_LightOnOffCounter_LightOnOffCounter_Value_WriteData
        DataServices_Diag_RWDI_LightOnOffCounter_LightOnOffCounter_Value_ConditionCheckRead
        DataServices_Diag_RWDI_LightOnOffCounter_LightOnOffCounter_Value_ReadData
        DataServices_Diag_VM_HardwarePartNumber_WriteData
        DataServices_Diag_VM_HardwarePartNumber_ConditionCheckRead
        DataServices_Diag_VM_HardwarePartNumber_ReadData
        DataServices_DcmDspData_BootloaderVersion_ConditionCheckRead
        DataServices_DcmDspData_BootloaderVersion_ReadDataLength
        DataServices_DcmDspData_BootloaderVersion_ReadData
        DataServices_DcmDspData_ConfigurarionFingerprint_WriteData
        DataServices_DcmDspData_ConfigurarionFingerprint_ConditionCheckRead
        DataServices_DcmDspData_ConfigurarionFingerprint_ReadData
        DataServices_DcmDspData_ECUConfigurarion_WriteData
        DataServices_DcmDspData_ECUConfigurarion_ConditionCheckRead
        DataServices_DcmDspData_ECUConfigurarion_ReadData
        DataServices_DcmDspData_ECUDiagDatabaseVersion_ConditionCheckRead
        DataServices_DcmDspData_ECUDiagDatabaseVersion_ReadData
        DataServices_DcmDspData_ECUManufacturingDate_ConditionCheckRead
        DataServices_DcmDspData_ECUManufacturingDate_ReadData
        DataServices_DcmDspData_ECUProgrammingDate_ConditionCheckRead
        DataServices_DcmDspData_ECUProgrammingDate_ReadData
        DataServices_DcmDspData_ECUSerialNumber_ConditionCheckRead
        DataServices_DcmDspData_ECUSerialNumber_ReadData
        DataServices_DcmDspData_ReadActiveDiagSession_ConditionCheckRead
        DataServices_DcmDspData_ReadActiveDiagSession_ReadData
        DataServices_DcmDspData_ReadFingerprint_ConditionCheckRead
        DataServices_DcmDspData_ReadFingerprint_ReadData
        DataServices_DcmDspData_RepairShopFingerPrint_WriteData
        DataServices_DcmDspData_RepairShopFingerPrint_ConditionCheckRead
        DataServices_DcmDspData_RepairShopFingerPrint_ReadData
        DataServices_DcmDspData_SystemName_ConditionCheckRead
        DataServices_DcmDspData_SystemName_ReadDataLength
        DataServices_DcmDspData_SystemName_ReadData
        DataServices_DcmDspData_SystemSupplierIdData_ConditionCheckRead
        DataServices_DcmDspData_SystemSupplierIdData_ReadData
        DataServices_DcmDspData_VIN_WriteData
        DataServices_DcmDspData_VIN_ConditionCheckRead
        DataServices_DcmDspData_VIN_ReadData
        DataServices_DcmDspData_VM_CalibrarionPartNumber_WriteData
        DataServices_DcmDspData_VM_CalibrarionPartNumber_ConditionCheckRead
        DataServices_DcmDspData_VM_CalibrarionPartNumber_ReadData
        DataServices_DcmDspData_VM_CalibrationBaseline_WriteData
        DataServices_DcmDspData_VM_CalibrationBaseline_ConditionCheckRead
        DataServices_DcmDspData_VM_CalibrationBaseline_ReadData
        DataServices_DcmDspData_VM_FOTASpecialPartNumber_WriteData
        DataServices_DcmDspData_VM_FOTASpecialPartNumber_ConditionCheckRead
        DataServices_DcmDspData_VM_FOTASpecialPartNumber_ReadData
        DataServices_DcmDspData_VM_SoftwarBaseline_WriteData
        DataServices_DcmDspData_VM_SoftwarBaseline_ConditionCheckRead
        DataServices_DcmDspData_VM_SoftwarBaseline_ReadData
        DataServices_DcmDspData_VM_SofwarePartNumber_WriteData
        DataServices_DcmDspData_VM_SofwarePartNumber_ConditionCheckRead
        DataServices_DcmDspData_VM_SofwarePartNumber_ReadData
        DataServices_DcmDspData_VM_SparepartNumber_WriteData
        DataServices_DcmDspData_VM_SparepartNumber_ConditionCheckRead
        DataServices_DcmDspData_VM_SparepartNumber_ReadData
        DataServices_DcmDspData_VM_Specialdatabaseline_WriteData
        DataServices_DcmDspData_VM_Specialdatabaseline_ConditionCheckRead
        DataServices_DcmDspData_VM_Specialdatabaseline_ReadDataLength
        DataServices_DcmDspData_VM_Specialdatabaseline_ReadData
        DataServices_Diag_VM_HardwareBaseline_WriteData
        DataServices_Diag_VM_HardwareBaseline_ConditionCheckRead
        DataServices_Diag_VM_HardwareBaseline_ReadData
        SecurityAccess_Level_01_CompareKey
        SecurityAccess_Level_01_GetSeed
        SecurityAccess_Level_02_CompareKey
        SecurityAccess_Level_02_GetSeed
  swc implementation Communication_Read_APP_Implementation: behavior=Communication_Read_APP_InternalBehavior
